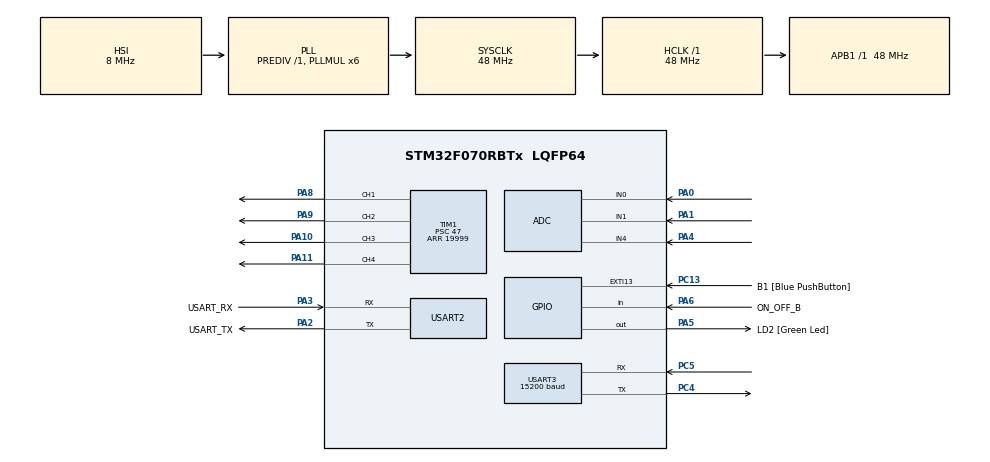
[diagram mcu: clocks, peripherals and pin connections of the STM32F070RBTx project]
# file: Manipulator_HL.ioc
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Mcu.Family=STM32F0
Mcu.Name=STM32F070RBTx
Mcu.Package=LQFP64
NVIC.USART3_4_IRQn=true\:0\:0\:false\:false\:true\:true\:true\:true
PA0.Mode=IN0
PA0.Signal=ADC_IN0
PA1.Mode=IN1
PA1.Signal=ADC_IN1
PA10.Signal=S_TIM1_CH3
PA11.Signal=S_TIM1_CH4
PA13.GPIO_Label=TMS
PA13.Mode=Serial_Wire
PA13.Signal=SYS_SWDIO
PA14.GPIO_Label=TCK
PA14.Mode=Serial_Wire
PA14.Signal=SYS_SWCLK
PA2.GPIO_Label=USART_TX
PA2.Mode=Asynchronous
PA2.Signal=USART2_TX
PA3.GPIO_Label=USART_RX
PA3.Mode=Asynchronous
PA3.Signal=USART2_RX
PA4.Mode=IN4
PA4.Signal=ADC_IN4
PA5.GPIO_Label=LD2 [Green Led]
PA5.Signal=GPIO_Output
PA6.GPIO_Label=ON_OFF_B
PA6.GPIO_PuPd=GPIO_PULLUP
PA6.Signal=GPIO_Input
PA8.Signal=S_TIM1_CH1
PA9.Signal=S_TIM1_CH2
PC13.GPIO_Label=B1 [Blue PushButton]
PC13.GPIO_ModeDefaultEXTI=GPIO_MODE_IT_FALLING
PC13.Signal=GPXTI13
PC14-OSC32_IN.GPIO_Label=RCC_OSC32_IN
PC14-OSC32_IN.Mode=LSE-External-Oscillator
PC14-OSC32_IN.Signal=RCC_OSC32_IN
PC15-OSC32_OUT.GPIO_Label=RCC_OSC32_OUT
PC15-OSC32_OUT.Mode=LSE-External-Oscillator
PC15-OSC32_OUT.Signal=RCC_OSC32_OUT
PC4.Mode=Asynchronous
PC4.Signal=USART3_TX
PC5.Mode=Asynchronous
PC5.Signal=USART3_RX
PF0-OSC_IN.GPIO_Label=RCC_OSC_IN
PF0-OSC_IN.Mode=HSE-External-Clock-Source
PF0-OSC_IN.Signal=RCC_OSC_IN
PF1-OSC_OUT.GPIO_Label=RCC_OSC_OUT
PF1-OSC_OUT.Signal=RCC_OSC_OUT
ProjectManager.HeapSize=0x200
ProjectManager.StackSize=0x400
ProjectManager.TargetToolchain=STM32CubeIDE
RCC.AHBFreq_Value=48000000
RCC.APB1Freq_Value=48000000
RCC.APB1TimFreq_Value=48000000
RCC.HCLKFreq_Value=48000000
RCC.PLLMUL=RCC_PLL_MUL6
RCC.SYSCLKFreq_VALUE=48000000
RCC.SYSCLKSource=RCC_SYSCLKSOURCE_PLLCLK
SH.S_TIM1_CH1.0=TIM1_CH1,PWM Generation1 CH1
SH.S_TIM1_CH2.0=TIM1_CH2,PWM Generation2 CH2
SH.S_TIM1_CH3.0=TIM1_CH3,PWM Generation3 CH3
SH.S_TIM1_CH4.0=TIM1_CH4,PWM Generation4 CH4
TIM1.Channel-PWM\ Generation1\ CH1=TIM_CHANNEL_1
TIM1.Channel-PWM\ Generation2\ CH2=TIM_CHANNEL_2
TIM1.Channel-PWM\ Generation3\ CH3=TIM_CHANNEL_3
TIM1.Channel-PWM\ Generation4\ CH4=TIM_CHANNEL_4
TIM1.Period=19999
TIM1.Prescaler=47
TIM1.Pulse-PWM\ Generation1\ CH1=1000
TIM1.Pulse-PWM\ Generation2\ CH2=1000
TIM1.Pulse-PWM\ Generation3\ CH3=1000
TIM1.Pulse-PWM\ Generation4\ CH4=1000
USART2.VirtualMode-Asynchronous=VM_ASYNC
USART3.BaudRate=15200
USART3.VirtualMode-Asynchronous=VM_ASYNC
VP_TIM1_VS_ClockSourceINT.Mode=Internal
board=NUCLEO-F070RB

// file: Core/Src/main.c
/* USER CODE BEGIN Header */
/**
  ******************************************************************************
  * @file           : main.c
  * @brief          : Main program body
  ******************************************************************************
  * @attention
  *
  * Copyright (c) 2022 STMicroelectronics.
  * All rights reserved.
  *
  * This software is licensed under terms that can be found in the LICENSE file
  * in the root directory of this software component.
  * If no LICENSE file comes with this software, it is provided AS-IS.
  *
  ******************************************************************************
  */
/* USER CODE END Header */
#include "main.h"

ADC_HandleTypeDef hadc;

TIM_HandleTypeDef htim1;

UART_HandleTypeDef huart2;
UART_HandleTypeDef huart3;

void SystemClock_Config(void);
static void MX_GPIO_Init(void);
static void MX_USART2_UART_Init(void);
static void MX_ADC_Init(void);
static void MX_TIM1_Init(void);
static void MX_USART3_UART_Init(void);

/* USER CODE BEGIN 0 */
uint8_t byteRead;
/* USER CODE END 0 */

int main(void)
{

  /* MCU Configuration--------------------------------------------------------*/

  /* Reset of all peripherals, Initializes the Flash interface and the Systick. */
  HAL_Init();

  /* Configure the system clock */
  SystemClock_Config();

  /* Initialize all configured peripherals */
  MX_GPIO_Init();
  MX_USART2_UART_Init();
  MX_ADC_Init();
  MX_TIM1_Init();
  MX_USART3_UART_Init();
  /* USER CODE BEGIN 2 */
  HAL_TIM_PWM_Start(&htim1, TIM_CHANNEL_1);
  HAL_TIM_PWM_Start(&htim1, TIM_CHANNEL_2);
  HAL_TIM_PWM_Start(&htim1, TIM_CHANNEL_3);
  HAL_TIM_PWM_Start(&htim1, TIM_CHANNEL_4);
  __HAL_TIM_SET_COMPARE(&htim1, TIM_CHANNEL_1, 1000);
  __HAL_TIM_SET_COMPARE(&htim1, TIM_CHANNEL_2, 1000);
  __HAL_TIM_SET_COMPARE(&htim1, TIM_CHANNEL_3, 1000);
  __HAL_TIM_SET_COMPARE(&htim1, TIM_CHANNEL_4, 1000);
  HAL_UART_Receive_IT(&huart3, &byteRead, 1);
  /* USER CODE END 2 */

  /* Infinite loop */
  while (1)
  {

  }
}

void SystemClock_Config(void)
{
  RCC_OscInitTypeDef RCC_OscInitStruct = {0};
  RCC_ClkInitTypeDef RCC_ClkInitStruct = {0};

  /** Initializes the RCC Oscillators according to the specified parameters
  * in the RCC_OscInitTypeDef structure.
  */
  RCC_OscInitStruct.OscillatorType = RCC_OSCILLATORTYPE_HSI|RCC_OSCILLATORTYPE_HSI14;
  RCC_OscInitStruct.HSIState = RCC_HSI_ON;
  RCC_OscInitStruct.HSI14State = RCC_HSI14_ON;
  RCC_OscInitStruct.HSICalibrationValue = RCC_HSICALIBRATION_DEFAULT;
  RCC_OscInitStruct.HSI14CalibrationValue = 16;
  RCC_OscInitStruct.PLL.PLLState = RCC_PLL_ON;
  RCC_OscInitStruct.PLL.PLLSource = RCC_PLLSOURCE_HSI;
  RCC_OscInitStruct.PLL.PLLMUL = RCC_PLL_MUL6;
  RCC_OscInitStruct.PLL.PREDIV = RCC_PREDIV_DIV1;
  if (HAL_RCC_OscConfig(&RCC_OscInitStruct) != HAL_OK)
  {
    Error_Handler();
  }

  /** Initializes the CPU, AHB and APB buses clocks
  */
  RCC_ClkInitStruct.ClockType = RCC_CLOCKTYPE_HCLK|RCC_CLOCKTYPE_SYSCLK
                              |RCC_CLOCKTYPE_PCLK1;
  RCC_ClkInitStruct.SYSCLKSource = RCC_SYSCLKSOURCE_PLLCLK;
  RCC_ClkInitStruct.AHBCLKDivider = RCC_SYSCLK_DIV1;
  RCC_ClkInitStruct.APB1CLKDivider = RCC_HCLK_DIV1;

  if (HAL_RCC_ClockConfig(&RCC_ClkInitStruct, FLASH_LATENCY_1) != HAL_OK)
  {
    Error_Handler();
  }
}

static void MX_ADC_Init(void)
{

  ADC_ChannelConfTypeDef sConfig = {0};

  /** Configure the global features of the ADC (Clock, Resolution, Data Alignment and number of conversion)
  */
  hadc.Instance = ADC1;
  hadc.Init.ClockPrescaler = ADC_CLOCK_ASYNC_DIV1;
  hadc.Init.Resolution = ADC_RESOLUTION_12B;
  hadc.Init.DataAlign = ADC_DATAALIGN_RIGHT;
  hadc.Init.ScanConvMode = ADC_SCAN_DIRECTION_FORWARD;
  hadc.Init.EOCSelection = ADC_EOC_SINGLE_CONV;
  hadc.Init.LowPowerAutoWait = DISABLE;
  hadc.Init.LowPowerAutoPowerOff = DISABLE;
  hadc.Init.ContinuousConvMode = DISABLE;
  hadc.Init.DiscontinuousConvMode = DISABLE;
  hadc.Init.ExternalTrigConv = ADC_SOFTWARE_START;
  hadc.Init.ExternalTrigConvEdge = ADC_EXTERNALTRIGCONVEDGE_NONE;
  hadc.Init.DMAContinuousRequests = DISABLE;
  hadc.Init.Overrun = ADC_OVR_DATA_PRESERVED;
  if (HAL_ADC_Init(&hadc) != HAL_OK)
  {
    Error_Handler();
  }

  /** Configure for the selected ADC regular channel to be converted.
  */
  sConfig.Channel = ADC_CHANNEL_0;
  sConfig.Rank = ADC_RANK_CHANNEL_NUMBER;
  sConfig.SamplingTime = ADC_SAMPLETIME_1CYCLE_5;
  if (HAL_ADC_ConfigChannel(&hadc, &sConfig) != HAL_OK)
  {
    Error_Handler();
  }

  /** Configure for the selected ADC regular channel to be converted.
  */
  sConfig.Channel = ADC_CHANNEL_1;
  if (HAL_ADC_ConfigChannel(&hadc, &sConfig) != HAL_OK)
  {
    Error_Handler();
  }

  /** Configure for the selected ADC regular channel to be converted.
  */
  sConfig.Channel = ADC_CHANNEL_4;
  if (HAL_ADC_ConfigChannel(&hadc, &sConfig) != HAL_OK)
  {
    Error_Handler();
  }

}

static void MX_TIM1_Init(void)
{

  TIM_ClockConfigTypeDef sClockSourceConfig = {0};
  TIM_MasterConfigTypeDef sMasterConfig = {0};
  TIM_OC_InitTypeDef sConfigOC = {0};
  TIM_BreakDeadTimeConfigTypeDef sBreakDeadTimeConfig = {0};

  htim1.Instance = TIM1;
  htim1.Init.Prescaler = 47;
  htim1.Init.CounterMode = TIM_COUNTERMODE_UP;
  htim1.Init.Period = 19999;
  htim1.Init.ClockDivision = TIM_CLOCKDIVISION_DIV1;
  htim1.Init.RepetitionCounter = 0;
  htim1.Init.AutoReloadPreload = TIM_AUTORELOAD_PRELOAD_DISABLE;
  if (HAL_TIM_Base_Init(&htim1) != HAL_OK)
  {
    Error_Handler();
  }
  sClockSourceConfig.ClockSource = TIM_CLOCKSOURCE_INTERNAL;
  if (HAL_TIM_ConfigClockSource(&htim1, &sClockSourceConfig) != HAL_OK)
  {
    Error_Handler();
  }
  if (HAL_TIM_PWM_Init(&htim1) != HAL_OK)
  {
    Error_Handler();
  }
  sMasterConfig.MasterOutputTrigger = TIM_TRGO_RESET;
  sMasterConfig.MasterSlaveMode = TIM_MASTERSLAVEMODE_DISABLE;
  if (HAL_TIMEx_MasterConfigSynchronization(&htim1, &sMasterConfig) != HAL_OK)
  {
    Error_Handler();
  }
  sConfigOC.OCMode = TIM_OCMODE_PWM1;
  sConfigOC.Pulse = 1000;
  sConfigOC.OCPolarity = TIM_OCPOLARITY_HIGH;
  sConfigOC.OCNPolarity = TIM_OCNPOLARITY_HIGH;
  sConfigOC.OCFastMode = TIM_OCFAST_DISABLE;
  sConfigOC.OCIdleState = TIM_OCIDLESTATE_RESET;
  sConfigOC.OCNIdleState = TIM_OCNIDLESTATE_RESET;
  if (HAL_TIM_PWM_ConfigChannel(&htim1, &sConfigOC, TIM_CHANNEL_1) != HAL_OK)
  {
    Error_Handler();
  }
  if (HAL_TIM_PWM_ConfigChannel(&htim1, &sConfigOC, TIM_CHANNEL_2) != HAL_OK)
  {
    Error_Handler();
  }
  if (HAL_TIM_PWM_ConfigChannel(&htim1, &sConfigOC, TIM_CHANNEL_3) != HAL_OK)
  {
    Error_Handler();
  }
  if (HAL_TIM_PWM_ConfigChannel(&htim1, &sConfigOC, TIM_CHANNEL_4) != HAL_OK)
  {
    Error_Handler();
  }
  sBreakDeadTimeConfig.OffStateRunMode = TIM_OSSR_DISABLE;
  sBreakDeadTimeConfig.OffStateIDLEMode = TIM_OSSI_DISABLE;
  sBreakDeadTimeConfig.LockLevel = TIM_LOCKLEVEL_OFF;
  sBreakDeadTimeConfig.DeadTime = 0;
  sBreakDeadTimeConfig.BreakState = TIM_BREAK_DISABLE;
  sBreakDeadTimeConfig.BreakPolarity = TIM_BREAKPOLARITY_HIGH;
  sBreakDeadTimeConfig.AutomaticOutput = TIM_AUTOMATICOUTPUT_DISABLE;
  if (HAL_TIMEx_ConfigBreakDeadTime(&htim1, &sBreakDeadTimeConfig) != HAL_OK)
  {
    Error_Handler();
  }
  HAL_TIM_MspPostInit(&htim1);

}

static void MX_USART2_UART_Init(void)
{

  huart2.Instance = USART2;
  huart2.Init.BaudRate = 38400;
  huart2.Init.WordLength = UART_WORDLENGTH_8B;
  huart2.Init.StopBits = UART_STOPBITS_1;
  huart2.Init.Parity = UART_PARITY_NONE;
  huart2.Init.Mode = UART_MODE_TX_RX;
  huart2.Init.HwFlowCtl = UART_HWCONTROL_NONE;
  huart2.Init.OverSampling = UART_OVERSAMPLING_16;
  huart2.Init.OneBitSampling = UART_ONE_BIT_SAMPLE_DISABLE;
  huart2.AdvancedInit.AdvFeatureInit = UART_ADVFEATURE_NO_INIT;
  if (HAL_UART_Init(&huart2) != HAL_OK)
  {
    Error_Handler();
  }

}

static void MX_USART3_UART_Init(void)
{

  huart3.Instance = USART3;
  huart3.Init.BaudRate = 15200;
  huart3.Init.WordLength = UART_WORDLENGTH_8B;
  huart3.Init.StopBits = UART_STOPBITS_1;
  huart3.Init.Parity = UART_PARITY_NONE;
  huart3.Init.Mode = UART_MODE_TX_RX;
  huart3.Init.HwFlowCtl = UART_HWCONTROL_NONE;
  huart3.Init.OverSampling = UART_OVERSAMPLING_16;
  huart3.Init.OneBitSampling = UART_ONE_BIT_SAMPLE_DISABLE;
  huart3.AdvancedInit.AdvFeatureInit = UART_ADVFEATURE_NO_INIT;
  if (HAL_UART_Init(&huart3) != HAL_OK)
  {
    Error_Handler();
  }

}

static void MX_GPIO_Init(void)
{
  GPIO_InitTypeDef GPIO_InitStruct = {0};

  /* GPIO Ports Clock Enable */
  __HAL_RCC_GPIOC_CLK_ENABLE();
  __HAL_RCC_GPIOF_CLK_ENABLE();
  __HAL_RCC_GPIOA_CLK_ENABLE();

  /*Configure GPIO pin Output Level */
  HAL_GPIO_WritePin(LD2_GPIO_Port, LD2_Pin, GPIO_PIN_RESET);

  /*Configure GPIO pin : B1_Pin */
  GPIO_InitStruct.Pin = B1_Pin;
  GPIO_InitStruct.Mode = GPIO_MODE_IT_FALLING;
  GPIO_InitStruct.Pull = GPIO_NOPULL;
  HAL_GPIO_Init(B1_GPIO_Port, &GPIO_InitStruct);

  /*Configure GPIO pin : LD2_Pin */
  GPIO_InitStruct.Pin = LD2_Pin;
  GPIO_InitStruct.Mode = GPIO_MODE_OUTPUT_PP;
  GPIO_InitStruct.Pull = GPIO_NOPULL;
  GPIO_InitStruct.Speed = GPIO_SPEED_FREQ_LOW;
  HAL_GPIO_Init(LD2_GPIO_Port, &GPIO_InitStruct);

  /*Configure GPIO pin : ON_OFF_B_Pin */
  GPIO_InitStruct.Pin = ON_OFF_B_Pin;
  GPIO_InitStruct.Mode = GPIO_MODE_INPUT;
  GPIO_InitStruct.Pull = GPIO_PULLUP;
  HAL_GPIO_Init(ON_OFF_B_GPIO_Port, &GPIO_InitStruct);

}

/* USER CODE BEGIN 4 */
void HAL_UART_RxCpltCallback(UART_HandleTypeDef *huart)
{
	if(huart == &huart3)
	{

	}
	HAL_UART_Receive_IT(&huart3, &byteRead, 1);
}
/* USER CODE END 4 */

void Error_Handler(void)
{
  __disable_irq();
  while (1)
  {
  }
}
